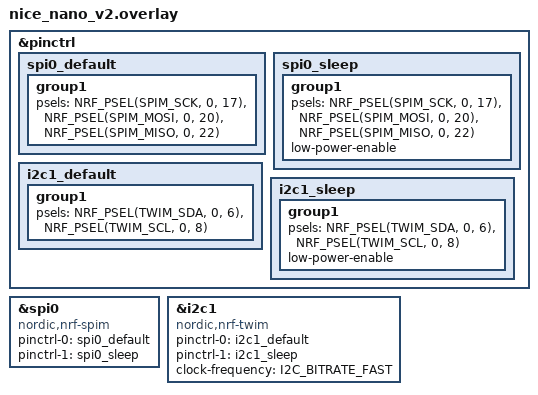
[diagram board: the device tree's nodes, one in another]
&pinctrl {
    spi0_default: spi0_default {
        group1 {
            psels = <NRF_PSEL(SPIM_SCK, 0, 17)>,
                    <NRF_PSEL(SPIM_MOSI, 0, 20)>,
                    <NRF_PSEL(SPIM_MISO, 0, 22)>;
        };
    };

    spi0_sleep: spi0_sleep {
        group1 {
            psels = <NRF_PSEL(SPIM_SCK, 0, 17)>,
                    <NRF_PSEL(SPIM_MOSI, 0, 20)>,
                    <NRF_PSEL(SPIM_MISO, 0, 22)>;
            low-power-enable;
        };
    };

    i2c1_default: i2c1_default {
        group1 {
            psels = <NRF_PSEL(TWIM_SDA, 0, 6)>,
                    <NRF_PSEL(TWIM_SCL, 0, 8)>;
        };
    };

    i2c1_sleep: i2c1_sleep {
        group1 {
            psels = <NRF_PSEL(TWIM_SDA, 0, 6)>,
                    <NRF_PSEL(TWIM_SCL, 0, 8)>;
            low-power-enable;
        };
    };
};

&spi0 {
    compatible = "nordic,nrf-spim";
    status = "okay"; // Explicitly enable the SPI peripheral
    pinctrl-0 = <&spi0_default>;
    pinctrl-1 = <&spi0_sleep>;
    pinctrl-names = "default", "sleep";
};

&i2c1 {
    compatible = "nordic,nrf-twim";
    status = "okay"; // Explicitly enable the I2C peripheral
    pinctrl-0 = <&i2c1_default>;
    pinctrl-1 = <&i2c1_sleep>;
    pinctrl-names = "default", "sleep";
    clock-frequency = <I2C_BITRATE_FAST>; // Set I2C speed to 400 kbps
};
